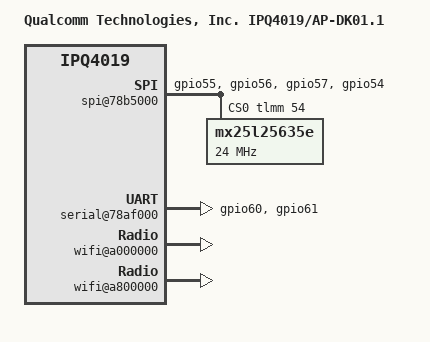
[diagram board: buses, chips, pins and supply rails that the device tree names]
#include <dt-bindings/gpio/gpio.h>
#include "qcom-ipq4019.dtsi"
/ {
	model = "Qualcomm Technologies, Inc. IPQ4019/AP-DK01.1";
	aliases {
		serial0 = &blsp1_uart1;
	};
	chosen {
		stdout-path = "serial0:115200n8";
	};
	soc {
		rng@22000 {
			status = "okay";
		};
		pinctrl@1000000 {
			serial_pins: serial_pinmux {
				mux {
					pins = "gpio60", "gpio61";
					function = "blsp_uart0";
					bias-disable;
				};
			};
			spi_0_pins: spi_0_pinmux {
				pinmux {
					function = "blsp_spi0";
					pins = "gpio55", "gpio56", "gpio57";
				};
				pinmux_cs {
					function = "gpio";
					pins = "gpio54";
				};
				pinconf {
					pins = "gpio55", "gpio56", "gpio57";
					drive-strength = <12>;
					bias-disable;
				};
				pinconf_cs {
					pins = "gpio54";
					drive-strength = <2>;
					bias-disable;
					output-high;
				};
			};
		};
		blsp_dma: dma-controller@7884000 {
			status = "okay";
		};
		spi@78b5000 {
			pinctrl-0 = <&spi_0_pins>;
			pinctrl-names = "default";
			status = "okay";
			cs-gpios = <&tlmm 54 GPIO_ACTIVE_HIGH>;
			mx25l25635e@0 {
				#address-cells = <1>;
				#size-cells = <1>;
				reg = <0>;
				compatible = "mx25l25635e";
				spi-max-frequency = <24000000>;
			};
		};
		serial@78af000 {
			pinctrl-0 = <&serial_pins>;
			pinctrl-names = "default";
			status = "okay";
		};
		cryptobam: dma-controller@8e04000 {
			status = "okay";
		};
		crypto@8e3a000 {
			status = "okay";
		};
		watchdog@b017000 {
			status = "okay";
		};
		wifi@a000000 {
			status = "okay";
		};
		wifi@a800000 {
			status = "okay";
		};
	};
};
